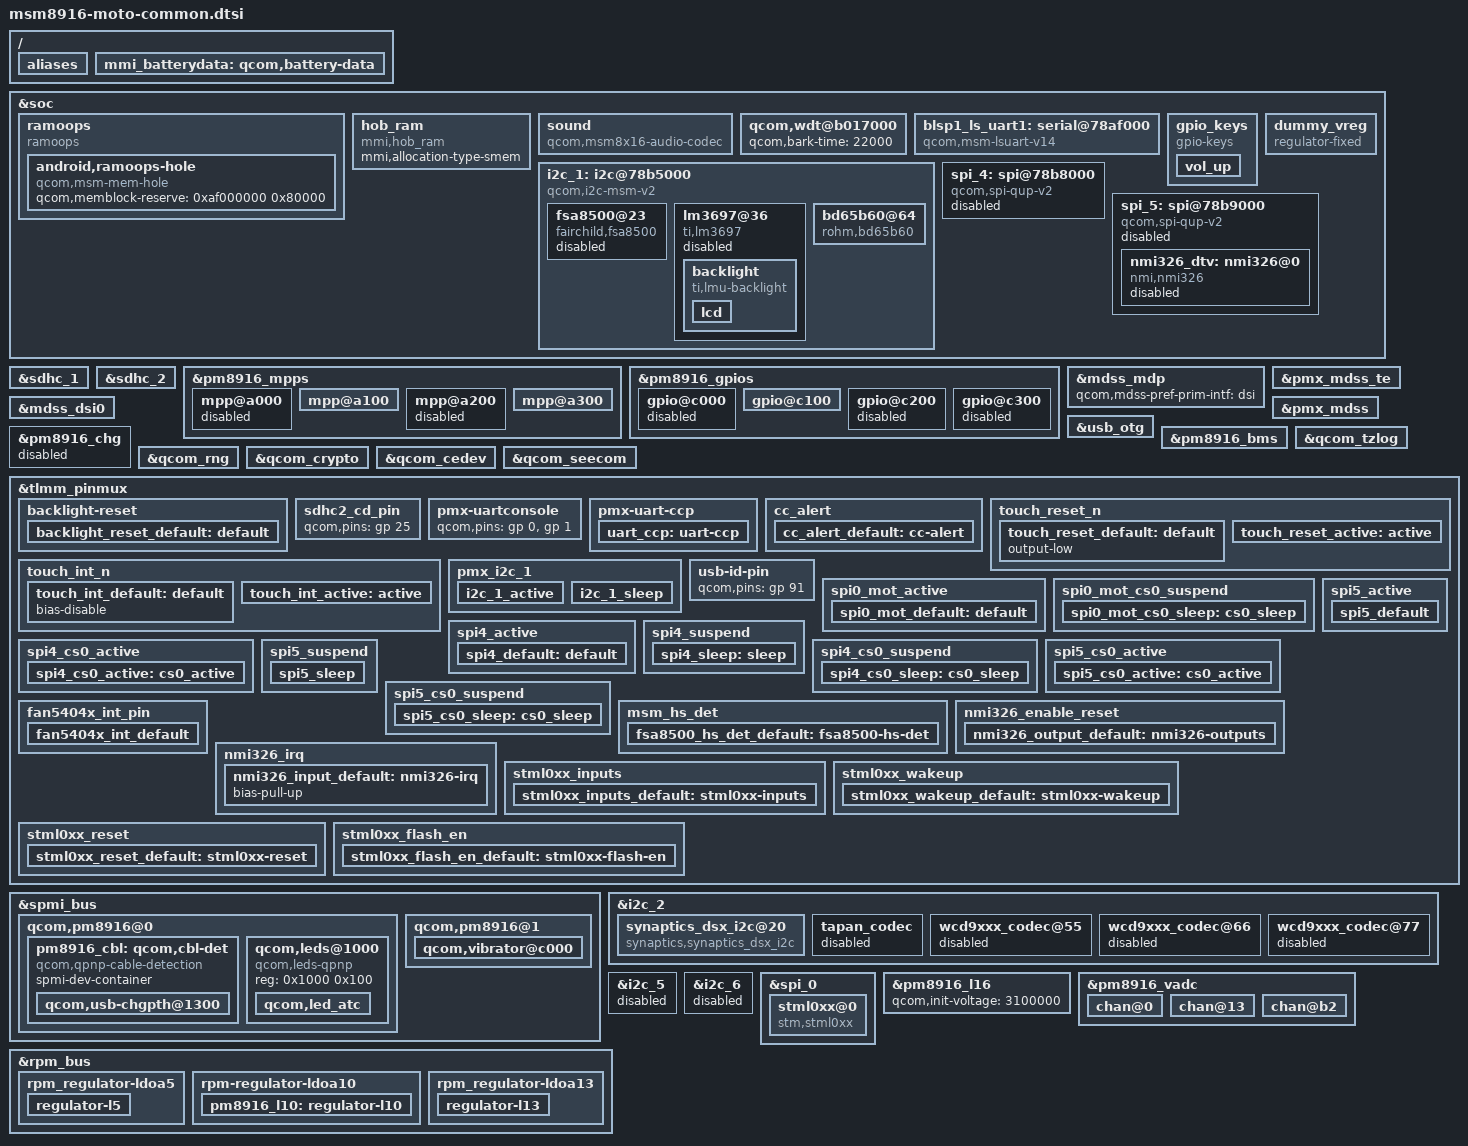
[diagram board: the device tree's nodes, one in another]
/* Copyright (c) 2014, Motorola Mobility LLC. All rights reserved.
*
* This program is free software; you can redistribute it and/or modify
* it under the terms of the GNU General Public License version 2 and
* only version 2 as published by the Free Software Foundation.
*
* This program is distributed in the hope that it will be useful,
* but WITHOUT ANY WARRANTY; without even the implied warranty of
* MERCHANTABILITY or FITNESS FOR A PARTICULAR PURPOSE.  See the
* GNU General Public License for more details.
*/

#include "msm8916.dtsi"
#include "msm8916-memory.dtsi"
#include "msm8916-pinctrl.dtsi"
#include "msm8916-camera-sensor-styx.dtsi"
#include "dsi-panel-mot-dummy-qhd-video.dtsi"

/ {
	aliases {
		serial0 = &blsp1_ls_uart1;
		spi4 = &spi_4; /* SPI4 controller device */
		spi5 = &spi_5; /* SPI5 controller device */
		i2c1 = &i2c_1;
	};
};

&soc {
	ramoops {
		compatible = "ramoops";
		status = "ok";

		android,ramoops-buffer-start = <0xaf000000>;
		android,ramoops-buffer-size = <0x80000>;
		android,ramoops-console-size = <0x40000>;
		android,ramoops-record-size = <0x3F800>;
		android,ramoops-annotate-size = <0x800>;
		android,ramoops-dump-oops = <0x1>;
		android,ramoops-hole {
			compatible = "qcom,msm-mem-hole";
			qcom,memblock-reserve = <0xaf000000 0x80000>;
		};
	};

	hob_ram {
		compatible = "mmi,hob_ram";
		mmi,allocation-type-smem;
	};

	sound {
		compatible = "qcom,msm8x16-audio-codec";
		qcom,model = "msm8x16-snd-card";
		qcom,msm-snd-card-id = <0>;
		qcom,msm-codec-type = "internal";
		qcom,msm-ext-pa = <0>;
		qcom,msm-mbhc-hphl-swh = <0>;
		qcom,msm-mbhc-gnd-swh = <0>;
		qcom,msm-hs-micbias-type = "internal";
		qcom,audio-routing =
			"RX_BIAS", "MCLK",
			"SPK_RX_BIAS", "MCLK",
			"INT_LDO_H", "MCLK",
			"MIC BIAS External", "Handset Mic",
			"MIC BIAS Internal2", "Headset Mic",
			"MIC BIAS External", "Secondary Mic",
			"AMIC1", "MIC BIAS External",
			"AMIC2", "MIC BIAS Internal2",
			"AMIC3", "MIC BIAS External";
		pinctrl-names = "cdc_lines_act",
				"cdc_lines_sus";
		pinctrl-0 = <&cdc_pdm_lines_act>;
		pinctrl-1 = <&cdc_pdm_lines_sus>;
	};

	qcom,wdt@b017000 {
		qcom,bark-time = <22000>;
	};
};

&soc {
	/delete-node/ serial@78af000;
	blsp1_ls_uart1: serial@78af000 {
		compatible = "qcom,msm-lsuart-v14";
		reg = <0x78af000 0x200>;
		interrupts = <0 107 0>;
		status = "ok";
		clocks = <&clock_gcc clk_gcc_blsp1_uart1_apps_clk>,
			 <&clock_gcc clk_gcc_blsp1_ahb_clk>;
		clock-names = "core_clk", "iface_clk";
		pinctrl-names = "default";
		pinctrl-0 = <&uart_console_sleep>;
	};
};

&soc {
	gpio_keys {
		compatible = "gpio-keys";
		input-name = "gpio-keys";
		pinctrl-names = "tlmm_gpio_key_active","tlmm_gpio_key_suspend";
		pinctrl-0 = <&gpio_key_active>;
		pinctrl-1 = <&gpio_key_suspend>;

		vol_up {
			label = "volume_up";
			gpios = <&msm_gpio 107 0x1>;
			linux,input-type = <1>;
			linux,code = <115>;
			gpio-key,wakeup;
			debounce-interval = <15>;
		};
	};
};

&sdhc_1 {
	vdd-supply = <&pm8916_l8>;
	qcom,vdd-voltage-level = <2900000 2900000>;
	qcom,vdd-current-level = <200 400000>;

	vdd-io-supply = <&pm8916_l5>;
	qcom,vdd-io-always-on;
	qcom,vdd-io-lpm-sup;
	qcom,vdd-io-voltage-level = <1800000 1800000>;
	qcom,vdd-io-current-level = <200 60000>;

	pinctrl-names = "active", "sleep";
	pinctrl-0 = <&sdc1_clk_on &sdc1_cmd_on &sdc1_data_on>;
	pinctrl-1 = <&sdc1_clk_off &sdc1_cmd_off &sdc1_data_off>;

	qcom,nonremovable;

	status = "ok";
};

&sdhc_2 {
	vdd-supply = <&pm8916_l11>;
	qcom,vdd-voltage-level = <2800000 2950000>;
	qcom,vdd-current-level = <15000 400000>;

	vdd-io-supply = <&pm8916_l12>;
	qcom,vdd-io-voltage-level = <1800000 2950000>;
	qcom,vdd-io-current-level = <200 50000>;

	pinctrl-names = "active", "sleep";
	pinctrl-0 = <&sdc2_clk_on &sdc2_cmd_on &sdc2_data_on &sdc2_cd_on>;
	pinctrl-1 = <&sdc2_clk_off &sdc2_cmd_off &sdc2_data_off &sdc2_cd_off>;

	#address-cells = <0>;
	interrupt-parent = <&sdhc_2>;
	interrupts = <0 1 2>;
	#interrupt-cells = <1>;
	interrupt-map-mask = <0xffffffff>;
	interrupt-map = <0 &intc 0 125 0
			1 &intc 0 221 0
			2 &msm_gpio 25 0>;
	interrupt-names = "hc_irq", "pwr_irq", "status_irq";
	cd-gpios = <&msm_gpio 25 0x1>;

	status = "ok";
};

&pm8916_mpps {
	mpp@a000 { /* MPP 1 */
		/* VDD_PX */
		status = "disabled";
	};

	mpp@a100 { /* MPP 2 */
		/* CCP_RESOUT_N */
		status = "ok";
		qcom,mode = <0>;      /* Digital Input */
		qcom,vin-sel = <2>;   /* VIN 2 (1.8V) */
		qcom,src-sel = <0>;   /* GPIO */
		qcom,master-en = <1>; /* Enable MPP */
	};

	mpp@a200 { /* MPP 3 */
		/* VREF DAC */
		status = "disabled";
	};

	mpp@a300 { /* MPP 4 */
		qcom,mode = <4>;      /* QPNP_PIN_MODE_AIN */
		qcom,ain-route = <3>; /* QPNP_PIN_AIN_AMUX_CH8 */
		qcom,master-en = <1>; /* Enable MPP */
	};
};

&pm8916_gpios {
	gpio@c000 { /* GPIO 1 */
		/* Battery UICC Alarm */
		status = "disabled";
	};

	gpio@c100 { /* GPIO 2 */
		/* NFC_CLK_REQ */
		qcom,mode = <0>; /* QPNP_PIN_MODE_DIG_IN */
		qcom,pull = <5>; /* QPNP_PIN_PULL_NO */
		qcom,vin-sel = <2>; /* QPNP_PIN_VIN2 */
		qcom,src-sel = <2>; /* QPNP_PIN_SEL_FUNC_1 */
		qcom,master-en = <1>;
	};

	gpio@c200 { /* GPIO 3 */
		/* Not connected */
		status = "disabled";
	};

	gpio@c300 { /* GPIO 4 */
		/* Not connected */
		status = "disabled";
	};
};

&mdss_mdp {
	qcom,mdss-pref-prim-intf = "dsi";
};

&pmx_mdss_te {
	qcom,num-grp-pins = <1>;
	qcom,pins = <&gp 24>;
};

&mdss_dsi0 {
	pinctrl-names = "mdss_default", "mdss_sleep";
	pinctrl-0 = <&mdss_dsi_active &mdss_te_active>;
	pinctrl-1 = <&mdss_dsi_suspend &mdss_te_suspend>;
	qcom,platform-reset-gpio = <&msm_gpio 78 0>;
};

&pmx_mdss {
	qcom,num-grp-pins = <1>;
	qcom,pins = <&gp 78>;
};

&usb_otg {
	qcom,hsusb-otg-mode = <3>;
	qcom,usbid-gpio = <&msm_gpio 91 0>;
	pinctrl-names = "default";
	pinctrl-0 = <&usbid_default>;
	vbus_otg-supply = <&fan54046>;
};

&pm8916_chg {
	status = "ok";
};

/ {
	mmi_batterydata: qcom,battery-data {
		qcom,rpull-up-kohm = <100>;
		qcom,vref-batt-therm = <1800000>;
	};
};

&pm8916_bms {
	status = "ok";
	qcom,battery-data = <&mmi_batterydata>;
};

&qcom_tzlog {
	status = "okay";
};

&qcom_rng {
	status = "okay";
};

&qcom_crypto {
	status = "okay";
};

&qcom_cedev {
	status = "okay";
};

&qcom_seecom {
	status = "okay";
};
&tlmm_pinmux {
	backlight-reset {
		qcom,pins = <&gp 36>;
		qcom,num-grp-pins = <1>;
		qcom,pin-func = <0>;
		label = "backlight-reset";

		backlight_reset_default: default {
			drive-strength = <2>;
			bias-pull-down;
			output-high;
		};
	};

	sdhc2_cd_pin {
		qcom,pins = <&gp 25>;
	};

	pmx-uartconsole {
		qcom,pins = <&gp 0>, <&gp 1>;
	};

	pmx-uart-ccp {
		qcom,pins = <&gp 4>, <&gp 5>;
		qcom,num-grp-pins = <2>;
		qcom,pin-func = <2>;
		label = "uart-ccp";

		uart_ccp: uart-ccp {
			drive-strength = <2>;
			bias-pull-down;
		};
	};

	cc_alert {
		qcom,pins = <&gp 12>;
		qcom,num-grp-pins = <1>;
		qcom,pin-func = <0>;
		label = "cc-alert";

		cc_alert_default: cc-alert {
			drive-strength = <2>;
			bias-pull-up;
		};
	};

	touch_reset_n {
		qcom,pins = <&gp 20>;
		qcom,num-grp-pins = <1>;
		qcom,pin-func = <0>;
		label = "touch-reset";

		touch_reset_default: default {
			output-low;
		};

		touch_reset_active: active {
			drive-strength = <2>;
			bias-pull-up; /* pull-up */
		};
	};

	touch_int_n {
		qcom,pins = <&gp 21>;
		qcom,num-grp-pins = <1>;
		qcom,pin-func = <0>;
		label = "touch-int";

		touch_int_default: default {
			bias-disable;
		};

		touch_int_active: active {
			drive-strength = <2>;
			bias-pull-up; /* pull-up */
		};
	};

	pmx_i2c_1 {
		/* CLK, DATA */
		qcom,pins = <&gp 3>, <&gp 2>;
		qcom,num-grp-pins = <2>;
		qcom,pin-func = <3>;
		label = "pmx_i2c_1";

		i2c_1_active: i2c_1_active {
			drive-strength = <2>; /* 2 MA */
			bias-disable;         /* No PULL */
		};

		i2c_1_sleep: i2c_1_sleep {
			drive-strength = <2>; /* 2 MA */
			bias-disable;	      /* No PULL */
		};
	};

        usb-id-pin {
                qcom,pins = <&gp 91>;
        };

	spi0_mot_active {
		/* MOSI, MISO, CLK */
		qcom,pins = <&gp 8>, <&gp 9>, <&gp 11>;
		qcom,num-grp-pins = <3>;
		qcom,pin-func = <1>;
		label = "spi0-mot-active";
		/* active state */
		spi0_mot_default: default {
			drive-strength = <2>; /* 2 MA */
			bias-disable = <0>; /* No PULL */
		};
	};

	spi0_mot_cs0_suspend {
		/* CS */
		qcom,pins = <&gp 10>;
		qcom,num-grp-pins = <1>;
		qcom,pin-func = <0>;
		label = "spi0-mot-cs0-suspend";
		spi0_mot_cs0_sleep: cs0_sleep {
			drive-strength = <2>;
			bias-disable = <0>;
			output-high;
		};
	};

	spi4_active {
		/* MOSI, MISO, CLK */
		qcom,pins = <&gp 12>, <&gp 13>, <&gp 15>;
		qcom,num-grp-pins = <3>;
		qcom,pin-func = <1>;
		label = "spi4-active";
		/* active state */
		spi4_default: default {
			drive-strength = <12>; /* 12 MA */
			bias-disable = <0>; /* No PULL */
		};
	};

	spi4_suspend {
		/* MOSI, MISO, CLK */
		qcom,pins = <&gp 12>, <&gp 13>, <&gp 15>;
		qcom,num-grp-pins = <3>;
		qcom,pin-func = <0>;
		label = "spi4-suspend";
		/* suspended state */
		spi4_sleep: sleep {
			drive-strength = <2>; /* 2 MA */
			bias-disable = <0>; /* No PULL */
		};
	};

	spi4_cs0_active {
		/* CS */
		qcom,pins = <&gp 14>;
		qcom,num-grp-pins = <1>;
		qcom,pin-func = <1>;
		label = "spi4-cs0-active";
		spi4_cs0_active: cs0_active {
			drive-strength = <2>;
			bias-disable = <0>;
		};
	};


	spi4_cs0_suspend {
		/* CS */
		qcom,pins = <&gp 14>;
		qcom,num-grp-pins = <1>;
		qcom,pin-func = <0>;
		label = "spi4-cs0-suspend";
		spi4_cs0_sleep: cs0_sleep {
			drive-strength = <2>;
			bias-disable = <0>;
		};
	};

	spi5_active {
		/* MOSI, MISO, CLK */
		qcom,pins = <&gp 16>, <&gp 17>, <&gp 19>;
		qcom,num-grp-pins = <3>;
		qcom,pin-func = <1>;
		label = "spi5-active";
		/* active state */
		spi5_default: spi5_default {
			drive-strength = <12>; /* 12 MA */
			bias-disable = <0>; /* No PULL */
		};
	};

	spi5_suspend {
		/* MOSI, MISO, CLK */
		qcom,pins = <&gp 16>, <&gp 17>, <&gp 19>;
		qcom,num-grp-pins = <3>;
		qcom,pin-func = <0>;
		label = "spi5-suspend";
		/* suspended state */
		spi5_sleep: spi5_sleep {
			drive-strength = <2>; /* 2 MA */
			bias-disable = <0>; /* No PULL */
		};
	};

	spi5_cs0_active {
		/* CS */
		qcom,pins = <&gp 18>;
		qcom,num-grp-pins = <1>;
		qcom,pin-func = <1>;
		label = "spi5-cs0-active";
		spi5_cs0_active: cs0_active {
			drive-strength = <2>;
			bias-disable = <0>;
		};
	};


	spi5_cs0_suspend {
		/* CS */
		qcom,pins = <&gp 18>;
		qcom,num-grp-pins = <1>;
		qcom,pin-func = <0>;
		label = "spi5-cs0-suspend";
		spi5_cs0_sleep: cs0_sleep {
			drive-strength = <2>;
			bias-disable = <0>;
		};
	};

	fan5404x_int_pin {
		qcom,pins = <&gp 62>;
		qcom,num-grp-pins = <1>;
		qcom,pin-func = <0>;
		label = "fan5404x_int_gpio";
		fan5404x_int_default: fan5404x_int_default {
			drive-strength = <2>;	/* 2 MA */
			bias-pull-up;		/* PULL UP*/
		};
	};

	msm_hs_det {
		qcom,pins = <&gp 69>;
		qcom,num-grp-pins = <1>;
		qcom,pin-func = <0>;
		label = "msm-hs-det";

		fsa8500_hs_det_default: fsa8500-hs-det {
			drive-strength = <2>;
			bias-pull-up; /* pull up */
		};
	};

	nmi326_enable_reset {
		qcom,pins = <&gp 97>, <&gp 98>;
		qcom,num-grp-pins = <2>;
		qcom,pin-func = <0>;
		label = "nmi326-outputs";

		nmi326_output_default: nmi326-outputs {
			drive-strength = <2>;
			bias-disable; /* no pull */
			output-low;
		};
	};

	nmi326_irq {
		qcom,pins = <&gp 111>;
		qcom,num-grp-pins = <1>;
		qcom,pin-func = <0>;
		label = "nmi326-irq";

		nmi326_input_default: nmi326-irq {
			bias-pull-up; /* pull up */
		};
	};

	/* IRQ, WakeIRQ, SPI Data Ack, SPI Ready for Receive */
	stml0xx_inputs {
		qcom,pins = <&gp 115>, <&gp 113>, <&gp 38>, <&gp 4>;
		qcom,num-grp-pins = <4>;
		qcom,pin-func = <0>;
		label = "stml0xx-inputs";

		stml0xx_inputs_default: stml0xx-inputs {
			bias-disable;         /* no pull */
			drive-strength = <2>;
		};
	};

	stml0xx_wakeup {
		qcom,pins = <&gp 110>;
		qcom,num-grp-pins = <1>;
		qcom,pin-func = <0>;
		label = "stml0xx-wakeup";

		stml0xx_wakeup_default: stml0xx-wakeup {
			bias-disable;         /* no pull */
			drive-strength = <2>;
			output-high;
		};
	};

	stml0xx_reset {
		qcom,pins = <&gp 120>;
		qcom,num-grp-pins = <1>;
		qcom,pin-func = <0>;
		label = "stml0xx-reset";

		stml0xx_reset_default: stml0xx-reset {
			bias-disable;         /* no pull */
			drive-strength = <2>;
			output-high;
		};
	};

	stml0xx_flash_en {
		qcom,pins = <&gp 121>;
		qcom,num-grp-pins = <1>;
		qcom,pin-func = <0>;
		label = "stml0xx-flash-en";

		stml0xx_flash_en_default: stml0xx-flash-en {
			bias-disable;         /* no pull */
			drive-strength = <2>;
			output-low;
		};
	};
};

&spmi_bus {
	qcom,pm8916@0 {
		pm8916_cbl: qcom,cbl-det {
			spmi-dev-container;
			compatible = "qcom,qpnp-cable-detection";
			#address-cells = <1>;
			#size-cells = <1>;

			qcom,usb-chgpth@1300 {
				reg = <0x1300 0x100>;
				interrupts =	<0 0x13 0x4>,
						<0 0x13 0x2>,
						<0 0x13 0x1>;
				interrupt-names =	"usb-over-temp",
							"chg-gone",
							"usbin-valid";
			};
		};

		qcom,leds@1000 {
			status = "ok";
			reg = <0x1000 0x100>;
			compatible = "qcom,leds-qpnp";
			qcom,led_atc {
				label = "atc";
				linux,name = "charging";
				qcom,max-current = <40>;
				qcom,id = <9>;
				qcom,mode = <2>;
			};
		};
	};
	qcom,pm8916@1 {
		qcom,vibrator@c000 {
			status = "okay";
			qcom,vib-timeout-ms = <30000>;
			qcom,vib-vtg-level-mV = <1800>;
			qcom,vib-vtg-level-mV-haptic = <2800>;
			qcom,vib-boot-up-vibe-ms = <100>;
		};
	};
};

&soc {
	dummy_vreg: dummy_vreg {
		compatible = "regulator-fixed";
		status = "ok";
		regulator-name = "dummy_vreg";
		regulator-always-on;
	};

	i2c_1: i2c@78b5000 { /* BLSP1 QUP1 */
		compatible = "qcom,i2c-msm-v2";
		#address-cells = <1>;
		#size-cells = <0>;
		reg-names = "qup_phys_addr", "bam_phys_addr";
		reg = <0x78b5000 0x600>,
		      <0x7884000 0x23000>;
		interrupt-names = "qup_irq", "bam_irq";
		interrupts = <0 95 0>, <0 238 0>;
		clocks = <&clock_gcc clk_gcc_blsp1_ahb_clk>,
			 <&clock_gcc clk_gcc_blsp1_qup1_i2c_apps_clk>;
		clock-names = "iface_clk", "core_clk";
		qcom,clk-freq-out = <100000>;
		qcom,clk-freq-in  = <19200000>;
		pinctrl-names = "i2c_active", "i2c_sleep";
		pinctrl-0 = <&i2c_1_active>;
		pinctrl-1 = <&i2c_1_sleep>;
		qcom,noise-rjct-scl = <0>;
		qcom,noise-rjct-sda = <0>;
		qcom,bam-pipe-idx-cons = <4>;
		qcom,bam-pipe-idx-prod = <5>;
		qcom,master-id = <86>;

		fsa8500@23 {
			status = "disabled";
			compatible = "fairchild,fsa8500";
			reg = <0x23>;
			gpios = <&msm_gpio 69 0x0>;
			hs_det_vdd-supply = <&dummy_vreg>; /* Connected to B-Plus */
			hs_det_micvdd-supply = <&pm8916_l6>;
			fsa8500-init-regs = <0x0c 0xa1>,
					    <0x0f 0xf9>;
			pinctrl-names = "default";
			pinctrl-0 = <&fsa8500_hs_det_default>;
		};

		lm3697@36 {
			status = "disabled";
			compatible = "ti,lm3697";
			reg = <0x36>;
			ti,enable-gpio = <&msm_gpio 36 0>;
			backlight {
				compatible = "ti,lmu-backlight", "ti,lm3697-backlight";
				lcd {
					hvled1-used;
					max-current-milliamp = /bits/ 8 <24>;
				};
			};
		};

		bd65b60@64 {
			compatible = "rohm,bd65b60";
			reg = <0x64>;
			linux,name = "wled:backlight";
			linux,default-trigger = "bkl-trigger";
			rohm,no-reset;
			rohm,led1-used;
			rohm,pwm-on;
			pinctrl-names = "default";
			pinctrl-0 = <&backlight_reset_default>;
		};
	};

	spi_4: spi@78b8000 { /* BLSP1 QUP4 */
		compatible = "qcom,spi-qup-v2";
		#address-cells = <1>;
		#size-cells = <0>;
		reg-names = "spi_physical", "spi_bam_physical";
		reg = <0x78b8000 0x600>,
		      <0x7884000 0x23000>;
		interrupt-names = "spi_irq", "spi_bam_irq";
		interrupts = <0 98 0>, <0 238 0>;
		spi-max-frequency = <19200000>;
		pinctrl-names = "default", "sleep";
		pinctrl-0 = <&spi4_default &spi4_cs0_active>;
		pinctrl-1 = <&spi4_sleep &spi4_cs0_sleep>;
		clocks = <&clock_gcc clk_gcc_blsp1_ahb_clk>,
			 <&clock_gcc clk_gcc_blsp1_qup4_spi_apps_clk>;
		clock-names = "iface_clk", "core_clk";
		qcom,infinite-mode = <0>;
		qcom,use-bam;
		qcom,use-pinctrl;
		qcom,ver-reg-exists;
		qcom,bam-consumer-pipe-index = <10>;
		qcom,bam-producer-pipe-index = <11>;
		qcom,master-id = <86>;
		status = "disabled";
	};

	spi_5: spi@78b9000 { /* BLSP1 QUP5 */
		compatible = "qcom,spi-qup-v2";
		#address-cells = <1>;
		#size-cells = <0>;
		reg-names = "spi_physical", "spi_bam_physical";
		reg = <0x78b9000 0x600>,
		      <0x7884000 0x23000>;
		interrupt-names = "spi_irq", "spi_bam_irq";
		interrupts = <0 99 0>, <0 238 0>;
		spi-max-frequency = <19200000>;
		pinctrl-names = "default", "sleep";
		pinctrl-0 = <&spi5_default &spi5_cs0_active>;
		pinctrl-1 = <&spi5_sleep &spi5_cs0_sleep>;
		clocks = <&clock_gcc clk_gcc_blsp1_ahb_clk>,
			 <&clock_gcc clk_gcc_blsp1_qup5_spi_apps_clk>;
		clock-names = "iface_clk", "core_clk";
		qcom,infinite-mode = <0>;
		qcom,use-bam;
		qcom,use-pinctrl;
		qcom,ver-reg-exists;
		qcom,bam-consumer-pipe-index = <12>;
		qcom,bam-producer-pipe-index = <13>;
		qcom,master-id = <86>;
		status = "disabled";

		nmi326_dtv: nmi326@0 {
			status = "disabled";
			compatible = "nmi,nmi326";
			reg = <0>;
			spi-max-frequency = <9600000>;
			irq-gpio = <&msm_gpio 111 0>;
			reset-gpio = <&msm_gpio 98 0>;
			enable-gpio = <&msm_gpio 97 0>;
			enable-active-high;
			pinctrl-names = "default";
			pinctrl-0 = <&nmi326_output_default &nmi326_input_default>;
			isdbt_vdd-supply = <&pm8916_l2>;
		};

	};
};

&i2c_2 {
	synaptics_dsx_i2c@20 {
		compatible = "synaptics,synaptics_dsx_i2c";
		reg = <0x20>;
		interrupt-parent = <&msm_gpio>;
		interrupts = <21 0>;
		gpios = <&msm_gpio 21 0>, /* IRQ */
			<&msm_gpio 20 0>; /* RESET */
		touch_vdd-supply = <&pm8916_l16>;
		synaptics,normal-mode = <1>;
		synaptics,gpio-config;
		pinctrl-names = "default", "active";
		pinctrl-0 = <&touch_reset_default &touch_int_default>;
		pinctrl-1 = <&touch_reset_active &touch_int_active>;
	};

	tapan_codec {
		status = "disable";
	};

	wcd9xxx_codec@55 {
		status = "disabled";
	};

	wcd9xxx_codec@66 {
		status = "disabled";
	};

	wcd9xxx_codec@77 {
		status = "disabled";
	};
};

&i2c_5 {
	status = "disabled";
};

&i2c_6 {
	status = "disabled";
};

&spi_0 {
	spi-max-frequency = <8000000>;
	pinctrl-0 = <&spi0_mot_default &spi0_cs0_active>;
	pinctrl-1 = <&spi0_sleep &spi0_mot_cs0_sleep>;

	/delete-property/ qcom,use-bam;
	/delete-node/ lattice,spi-usb@0;

	stml0xx@0 {
		compatible = "stm,stml0xx";
		status = "okay";
		reg = <0>;
		spi-max-frequency = <8000000>;
		gpios = <&msm_gpio 115 0>,       /* IRQ */
			<&msm_gpio 120 0>,       /* RESET */
			<&msm_gpio 121 0>,       /* BSLEN */
			<&msm_gpio 113 0>,       /* WakeIRQ */
			<&msm_gpio 4 0>,         /* SPI Ready for Receive */
			<&msm_gpio 38 0>,        /* SPI Data Ack */
			<&msm_gpio 110 0>;       /* Wake Up Sensor Hub */
		lux_table = <5 50 100 1500 3000 8000>;
		brightness_table = <9 14 18 46 67 93 140>;
		bslen_pin_active_value = <1>;
		ct406_detect_threshold = <0x006E>;
		ct406_undetect_threshold = <0x0050>;
		ct406_recalibrate_threshold = <0x0064>;
		ct406_pulse_count = <0x04>;
		headset_detect_enable = <1>;
		headset_insertion_debounce = <0x01F4>;
		headset_removal_debounce = <0x0080>;
		headset_button_down_debounce = <0x0032>;
		headset_button_up_debounce = <0x0032>;
		headset_button_0-1_threshold = <0x0096>;
		headset_button_1-2_threshold = <0x012C>;
		headset_button_2-3_threshold = <0x01C2>;
		headset_button_3-upper_threshold = <0x02EE>;
		sensor1-supply = <&pm8916_l6>;
		sensor2-supply = <&pm8916_l17>;

		pinctrl-names = "default";
		pinctrl-0 = <&stml0xx_inputs_default
			     &stml0xx_wakeup_default
			     &stml0xx_reset_default
			     &stml0xx_flash_en_default>;
	};
};

&pm8916_l16 {
	qcom,init-voltage = <3100000>;
};

&rpm_bus {
	rpm_regulator-ldoa5 {
		status = "okay";
		regulator-l5 {
			status = "okay";
		};
	};

	rpm-regulator-ldoa10 {
		pm8916_l10: regulator-l10 {
			regulator-min-microvolt = <1800000>;
			regulator-max-microvolt = <1800000>;
			qcom,init-voltage = <1800000>;
		};
	};

	rpm_regulator-ldoa13 {
		status = "okay";
		regulator-l13 {
			status = "okay";
		};
	};
};

&pm8916_chg {
	status = "disabled";
};

&pm8916_bms {
	status = "ok";
	qcom,disable-bms;
};

&pm8916_vadc {
	chan@0 {
		label = "usb_in";
		reg = <0>;
		qcom,decimation = <0>;
		qcom,pre-div-channel-scaling = <7>;
		qcom,calibration-type = "absolute";
		qcom,scale-function = <0>;
		qcom,hw-settle-time = <0>;
		qcom,fast-avg-setup = <0>;
	};
	chan@13 {
		label = "msm_therm";
		reg = <0x13>;
		qcom,decimation = <0>;
		qcom,pre-div-channel-scaling = <0>;
		qcom,calibration-type = "ratiometric";
		qcom,scale-function = <2>;
		qcom,hw-settle-time = <2>;
		qcom,fast-avg-setup = <0>;
	};

	chan@b2 {
		label = "xo_therm_pu2";
		reg = <0xb2>;
		qcom,decimation = <0>;
		qcom,pre-div-channel-scaling = <0>;
		qcom,calibration-type = "ratiometric";
		qcom,scale-function = <4>;
		qcom,hw-settle-time = <2>;
		qcom,fast-avg-setup = <0>;
	};
};
